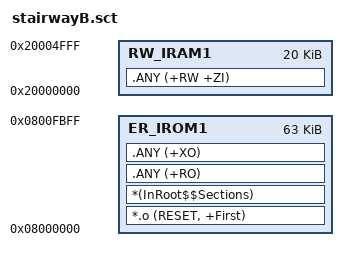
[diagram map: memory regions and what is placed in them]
; *************************************************************
; *** Scatter-Loading Description File generated by uVision ***
; *************************************************************

LR_IROM1 0x08000000 0x0000FC00  {    ; reserve the last 1 KiB Flash page for settings
  ER_IROM1 0x08000000 0x0000FC00  {  ; load address = execution address
   *.o (RESET, +First)
   *(InRoot$$Sections)
   .ANY (+RO)
   .ANY (+XO)
  }
  RW_IRAM1 0x20000000 0x00005000  {  ; RW data
   .ANY (+RW +ZI)
  }
}

